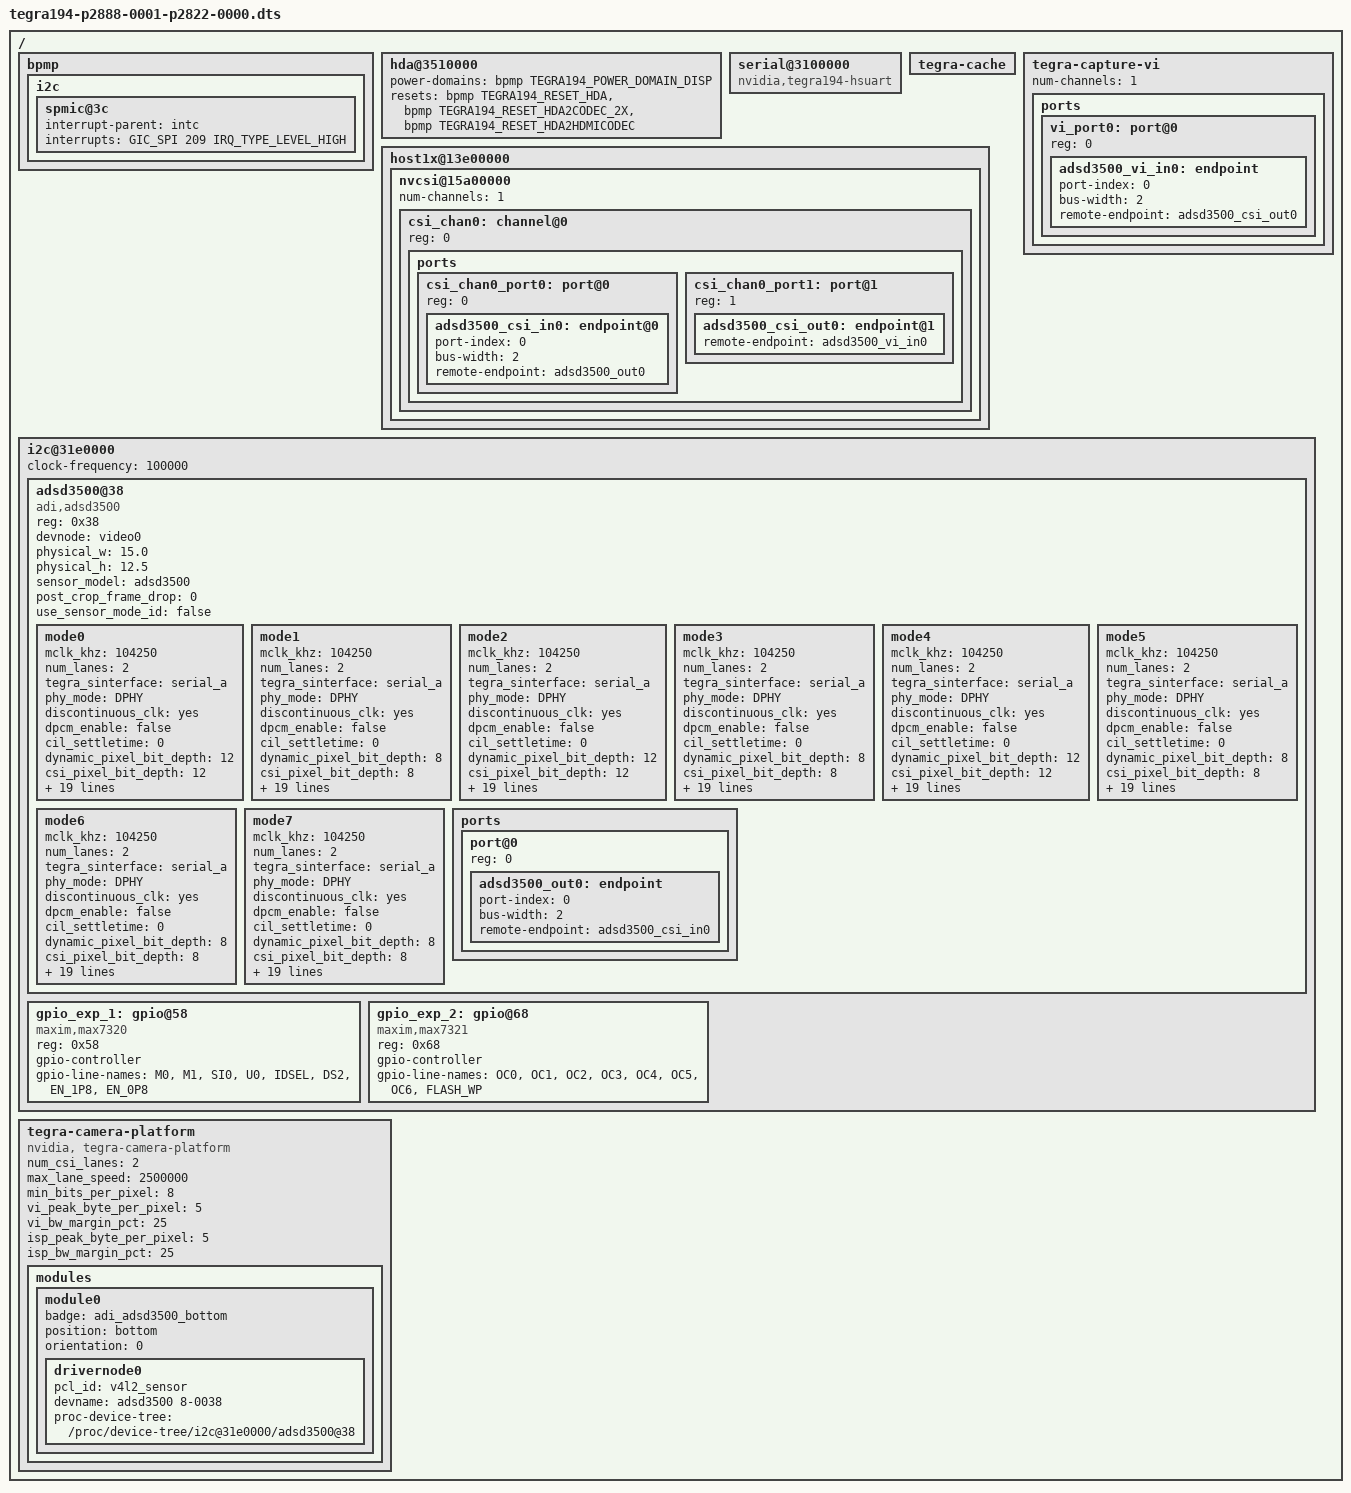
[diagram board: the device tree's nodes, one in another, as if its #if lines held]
/*
 * Copyright (c) 2017-2021, NVIDIA CORPORATION.  All rights reserved.
 *
 * This program is free software; you can redistribute it and/or modify it
 * under the terms and conditions of the GNU General Public License,
 * version 2, as published by the Free Software Foundation.
 *
 * This program is distributed in the hope it will be useful, but WITHOUT
 * ANY WARRANTY; without even the implied warranty of MERCHANTABILITY or
 * FITNESS FOR A PARTICULAR PURPOSE.  See the GNU General Public License for
 * more details.
 *
 * You should have received a copy of the GNU General Public License
 * along with this program.  If not, see <http://www.gnu.org/licenses/>.
 */

/*
 * Top level DTS file for CVM:P2888-0001 and CVB:P2822-0000.
 */
#include "common/tegra194-p2888-0001-p2822-0000-common.dtsi"
#include "common/tegra194-p2822-camera-modules.dtsi"
#include "common/tegra194-audio-p2822-0000.dtsi"

#if defined(LINUX_VERSION) && LINUX_VERSION >= 419

/ {
	/* FIXME: K5.4 overrides */
	bpmp {
		i2c {
			spmic@3c {
				interrupt-parent = <&intc>;
				interrupts = <GIC_SPI 209 IRQ_TYPE_LEVEL_HIGH>;
			};
		};
	};

	hda@3510000 {
		power-domains = <&bpmp TEGRA194_POWER_DOMAIN_DISP>;
		resets = <&bpmp TEGRA194_RESET_HDA>,
			 <&bpmp TEGRA194_RESET_HDA2CODEC_2X>,
			 <&bpmp TEGRA194_RESET_HDA2HDMICODEC>;
		reset-names = "hda", "hda2codec_2x", "hda2hdmi";
	};

	serial@3100000 {
		compatible = "nvidia,tegra194-hsuart";
	};

	tegra-cache {
		status = "okay";
	};

	tegra-capture-vi  {
		num-channels = <1>;
		ports {
			#address-cells = <1>;
			#size-cells = <0>;
			vi_port0: port@0 {
				reg = <0>;
				adsd3500_vi_in0: endpoint {
					port-index = <0>;
					bus-width = <2>;
					remote-endpoint = <&adsd3500_csi_out0>;
				};
			};
		};
	};

	host1x@13e00000 {
		nvcsi@15a00000 {
			num-channels = <1>;
			#address-cells = <1>;
			#size-cells = <0>;
			csi_chan0: channel@0 {
				reg = <0>;
				ports {
					#address-cells = <1>;
					#size-cells = <0>;
					csi_chan0_port0: port@0 {
						reg = <0>;
						adsd3500_csi_in0: endpoint@0 {
							port-index = <0>;
							bus-width = <2>;
							remote-endpoint = <&adsd3500_out0>;
						};
					};
					csi_chan0_port1: port@1 {
						reg = <1>;
						adsd3500_csi_out0: endpoint@1 {
							remote-endpoint = <&adsd3500_vi_in0>;
						};
					};
				};
			};
		};
	};
	
	i2c@31e0000 {
		clock-frequency = <100000>;
		adsd3500@38 {
			compatible = "adi,adsd3500";

			reg = <0x38>;
			devnode = "video0";

			/* Physical dimensions of sensor */
			physical_w = "15.0";
			physical_h = "12.5";

			sensor_model ="adsd3500";
			/* Define any required hw resources needed by driver */
			/* ie. clocks, io pins, power sources */

			/* Defines number of frames to be dropped by driver internally after applying */
			/* sensor crop settings. Some sensors send corrupt frames after applying */
			/* crop co-ordinates */
			post_crop_frame_drop = "0";
			
			/* enable CID_SENSOR_MODE_ID for sensor modes selection */
			use_sensor_mode_id = "false";

			/**
			* A modeX node is required to support v4l2 driver
			* implementation with NVIDIA camera software stack
			*
			* mclk_khz = "";
			* Standard MIPI driving clock, typically 24MHz
			*
			* num_lanes = "";
			* Number of lane channels sensor is programmed to output
			*
			* tegra_sinterface = "";
			* The base tegra serial interface lanes are connected to
			*
			* discontinuous_clk = "";
			* The sensor is programmed to use a discontinuous clock on MIPI lanes
			*
			* dpcm_enable = "true";
			* The sensor is programmed to use a DPCM modes
			*
			* cil_settletime = "";
			* MIPI lane settle time value.
			* A "0" value attempts to autocalibrate based on mclk_multiplier
			*
			* active_w = "";
			* Pixel active region width
			*
			* active_h = "";
			* Pixel active region height
			*
			* dynamic_pixel_bit_depth = "";
			* sensor dynamic bit depth for sensor mode
			*
			* csi_pixel_bit_depth = "";
			* sensor output bit depth for sensor mode
			*
			* mode_type="";
			* Sensor mode type, For eg: yuv, Rgb, bayer, bayer_wdr_pwl
			*
			* pixel_phase="";
			* Pixel phase for sensor mode, For eg: rggb, vyuy, rgb888
			*
			* readout_orientation = "0";
			* Based on camera module orientation.
			* Only change readout_orientation if you specifically
			* Program a different readout order for this mode
			*
			* line_length = "";
			* Pixel line length (width) for sensor mode.
			* This is used to calibrate features in our camera stack.
			*
			* mclk_multiplier = "";
			* Multiplier to MCLK to help time hardware capture sequence
			* TODO: Assign to PLL_Multiplier as well until fixed in core
			*
			* pix_clk_hz = "";
			* Sensor pixel clock used for calculations like exposure and framerate
			*
			* inherent_gain = "";
			* Gain obtained inherently from mode (ie. pixel binning)
			*
			* min_gain_val = ""; (floor to 6 decimal places)
			* max_gain_val = ""; (floor to 6 decimal places)
			* gain_step_pitch = ""; (floor to 6 decimal places, unit is db)
			* Gain limits for mode
			* if use_decibel_gain = "true", please set the gain as decibel
			*
			* min_exp_time = ""; (ceil to integer)
			* max_exp_time = ""; (ceil to integer)
			* Exposure Time limits for mode (us)
			*
			*
			* min_hdr_ratio = "";
			* max_hdr_ratio = "";
			* HDR Ratio limits for mode
			*
			* min_framerate = "";
			* max_framerate = "";
			* Framerate limits for mode (fps)
			*
			* embedded_metadata_height = "";
			* Sensor embedded metadata height in units of rows.
			* If sensor does not support embedded metadata value should be 0.
			*/

			mode0 {
				mclk_khz = "104250";
				num_lanes = "2";
				tegra_sinterface = "serial_a";
				phy_mode = "DPHY";
				discontinuous_clk = "yes";
				dpcm_enable = "false";
				cil_settletime = "0";
				dynamic_pixel_bit_depth = "12";
				csi_pixel_bit_depth = "12";
				mode_type = "bayer";
				pixel_phase = "bggr";

				active_w = "256";
				active_h = "320";
				readout_orientation = "0";
				line_length = "256";
				inherent_gain = "1";
				mclk_multiplier = "4";
				pix_clk_hz = "208333333";

				min_gain_val = "0"; /* dB */
				max_gain_val = "48"; /* dB */
				gain_step_pitch = "0.3";
				min_hdr_ratio = "1";
				max_hdr_ratio = "1";
				min_framerate = "1";
				max_framerate = "30";
				min_exp_time = "30";
				max_exp_time = "660000";
				embedded_metadata_height = "1";
			};
			mode1 {
				mclk_khz = "104250";
				num_lanes = "2";
				tegra_sinterface = "serial_a";
				phy_mode = "DPHY";
				discontinuous_clk = "yes";
				dpcm_enable = "false";
				cil_settletime = "0";
				dynamic_pixel_bit_depth = "8";
				csi_pixel_bit_depth = "8";
				mode_type = "bayer";
				pixel_phase = "bggr";

				active_w = "1280";
				active_h = "320";
				readout_orientation = "0";
				line_length = "1280";
				inherent_gain = "1";
				mclk_multiplier = "4";
				pix_clk_hz = "312500000";

				min_gain_val = "0";
				max_gain_val = "48";
				gain_step_pitch = "0.3";
				min_hdr_ratio = "1";
				max_hdr_ratio = "1";
				min_framerate = "1.5";
				max_framerate = "30";
				min_exp_time = "30";
				max_exp_time = "660000";
				embedded_metadata_height = "1";
			};
			mode2 {
				mclk_khz = "104250";
				num_lanes = "2";
				tegra_sinterface = "serial_a";
				phy_mode = "DPHY";
				discontinuous_clk = "yes";
				dpcm_enable = "false";
				cil_settletime = "0";
				dynamic_pixel_bit_depth = "12";
				csi_pixel_bit_depth = "12";
				mode_type = "bayer";
				pixel_phase = "bggr";

				active_w = "512";
				active_h = "512";
				readout_orientation = "0";
				line_length = "512";
				inherent_gain = "1";
				mclk_multiplier = "4";
				pix_clk_hz = "208333333";

				min_gain_val = "0";
				max_gain_val = "48";
				gain_step_pitch = "0.3";
				min_hdr_ratio = "1";
				max_hdr_ratio = "1";
				min_framerate = "1.5";
				max_framerate = "30";
				min_exp_time = "30";
				max_exp_time = "660000";
				embedded_metadata_height = "1";
			};
			mode3 {
				mclk_khz = "104250";
				num_lanes = "2";
				tegra_sinterface = "serial_a";
				phy_mode = "DPHY";
				discontinuous_clk = "yes";
				dpcm_enable = "false";
				cil_settletime = "0";
				dynamic_pixel_bit_depth = "8";
				csi_pixel_bit_depth = "8";
				mode_type = "bayer";
				pixel_phase = "bggr";

				active_w = "2560";
				active_h = "512";
				readout_orientation = "0";
				line_length = "2560";
				inherent_gain = "1";
				mclk_multiplier = "4";
				pix_clk_hz = "312500000";

				min_gain_val = "0";
				max_gain_val = "48";
				gain_step_pitch = "0.3";
				min_hdr_ratio = "1";
				max_hdr_ratio = "1";
				min_framerate = "1.5";
				max_framerate = "30";
				min_exp_time = "30";
				max_exp_time = "660000";
				embedded_metadata_height = "1";
			};
			mode4 {
				mclk_khz = "104250";
				num_lanes = "2";
				tegra_sinterface = "serial_a";
				phy_mode = "DPHY";
				discontinuous_clk = "yes";
				dpcm_enable = "false";
				cil_settletime = "0";
				dynamic_pixel_bit_depth = "12";
				csi_pixel_bit_depth = "12";
				mode_type = "bayer";
				pixel_phase = "bggr";

				active_w = "512";
				active_h = "640";
				readout_orientation = "0";
				line_length = "512";
				inherent_gain = "1";
				mclk_multiplier = "4";
				pix_clk_hz = "208333333";

				min_gain_val = "0";
				max_gain_val = "48";
				gain_step_pitch = "0.3";
				min_hdr_ratio = "1";
				max_hdr_ratio = "1";
				min_framerate = "1.5";
				max_framerate = "30";
				min_exp_time = "30";
				max_exp_time = "660000";
				embedded_metadata_height = "1";
			};
			mode5 {
				mclk_khz = "104250";
				num_lanes = "2";
				tegra_sinterface = "serial_a";
				phy_mode = "DPHY";
				discontinuous_clk = "yes";
				dpcm_enable = "false";
				cil_settletime = "0";
				dynamic_pixel_bit_depth = "8";
				csi_pixel_bit_depth = "8";
				mode_type = "bayer";
				pixel_phase = "bggr";

				active_w = "2048";
				active_h = "640";
				readout_orientation = "0";
				line_length = "2048";
				inherent_gain = "1";
				mclk_multiplier = "4";
				pix_clk_hz = "312500000";

				min_gain_val = "0";
				max_gain_val = "48";
				gain_step_pitch = "0.3";
				min_hdr_ratio = "1";
				max_hdr_ratio = "1";
				min_framerate = "1.5";
				max_framerate = "30";
				min_exp_time = "30";
				max_exp_time = "660000";
				embedded_metadata_height = "1";
			};
			mode6 {
				mclk_khz = "104250";
				num_lanes = "2";
				tegra_sinterface = "serial_a";
				phy_mode = "DPHY";
				discontinuous_clk = "yes";
				dpcm_enable = "false";
				cil_settletime = "0";
				dynamic_pixel_bit_depth = "8";
				csi_pixel_bit_depth = "8";
				mode_type = "bayer";
				pixel_phase = "bggr";

				active_w = "2560";
				active_h = "640";
				readout_orientation = "0";
				line_length = "2560";
				inherent_gain = "1";
				mclk_multiplier = "4";
				pix_clk_hz = "312500000";

				min_gain_val = "0";
				max_gain_val = "48";
				gain_step_pitch = "0.3";
				min_hdr_ratio = "1";
				max_hdr_ratio = "1";
				min_framerate = "1.5";
				max_framerate = "30";
				min_exp_time = "30";
				max_exp_time = "660000";
				embedded_metadata_height = "1";
			};
			mode7 {
				mclk_khz = "104250";
				num_lanes = "2";
				tegra_sinterface = "serial_a";
				phy_mode = "DPHY";
				discontinuous_clk = "yes";
				dpcm_enable = "false";
				cil_settletime = "0";
				dynamic_pixel_bit_depth = "8";
				csi_pixel_bit_depth = "8";
				mode_type = "bayer";
				pixel_phase = "bggr";

				active_w = "1024";
				active_h = "320";
				readout_orientation = "0";
				line_length = "256";
				inherent_gain = "1";
				mclk_multiplier = "4";
				pix_clk_hz = "208333333";

				min_gain_val = "0"; /* dB */
				max_gain_val = "48"; /* dB */
				gain_step_pitch = "0.3";
				min_hdr_ratio = "1";
				max_hdr_ratio = "1";
				min_framerate = "1";
				max_framerate = "30";
				min_exp_time = "30";
				max_exp_time = "660000";
				embedded_metadata_height = "1";
			};
			ports {
				#address-cells = <1>;
				#size-cells = <0>;
				port@0 {
					reg = <0>;
					adsd3500_out0: endpoint {
						port-index = <0>;
						bus-width = <2>;
						remote-endpoint = <&adsd3500_csi_in0>;
					};
				};
			};
		};

		gpio_exp_1: gpio@58 {
			compatible = "maxim,max7320";
			reg = <0x58>;
			gpio-controller;
			#gpio-cells = <2>;
			gpio-line-names = "M0", "M1", "SI0", "U0",
							  "IDSEL", "DS2", "EN_1P8", "EN_0P8";
		};

		gpio_exp_2: gpio@68 {
			compatible = "maxim,max7321";
			reg = <0x68>;
			gpio-controller;
			#gpio-cells = <2>;
			gpio-line-names = "OC0", "OC1", "OC2", "OC3",
							  "OC4", "OC5", "OC6", "FLASH_WP";
		};
	};
};

/ {
	tegra-camera-platform {
		compatible = "nvidia, tegra-camera-platform";
		/**
		* Physical settings to calculate max ISO BW
		*
		* num_csi_lanes = <>;
		* Total number of CSI lanes when all cameras are active
		*
		* max_lane_speed = <>;
		* Max lane speed in Kbit/s
		*
		* min_bits_per_pixel = <>;
		* Min bits per pixel
		*
		* vi_peak_byte_per_pixel = <>;
		* Max byte per pixel for the VI ISO case
		*
		* vi_bw_margin_pct = <>;
		* Vi bandwidth margin in percentage
		*
		* max_pixel_rate = <>;
		* Max pixel rate in Kpixel/s for the ISP ISO case
		*
		* isp_peak_byte_per_pixel = <>;
		* Max byte per pixel for the ISP ISO case
		*
		* isp_bw_margin_pct = <>;
		* Isp bandwidth margin in percentage
		*/
		num_csi_lanes = <2>;
		max_lane_speed = <2500000>;
		min_bits_per_pixel = <8>;
		vi_peak_byte_per_pixel = <5>;
		vi_bw_margin_pct = <25>;
		isp_peak_byte_per_pixel = <5>;
		isp_bw_margin_pct = <25>;

		/**
		 * The general guideline for naming badge_info contains 3 parts, and is as follows,
		 * The first part is the camera_board_id for the module; if the module is in a FFD
		 * platform, then use the platform name for this part.
		 * The second part contains the position of the module, ex. "rear" or "front".
		 * The third part contains the last 6 characters of a part number which is found
		 * in the module's specsheet from the vender.
		 */
		modules {
			module0 {
				badge = "adi_adsd3500_bottom";
				position = "bottom";
				orientation = "0";
				drivernode0 {
					/* Declare PCL support driver (classically known as guid)  */
					pcl_id = "v4l2_sensor";
					/* Driver v4l2 device name */
					devname = "adsd3500 8-0038";
					/* Declare the device-tree hierarchy to driver instance */
					proc-device-tree = "/proc/device-tree/i2c@31e0000/adsd3500@38";
				};
			};
		};
	};
};

#endif
